# ATSAMA5D28CLD1G device description
Architecture: CORTEX-A5; Family: SAMA5; Series: SAMA5D2
Registers are 32-bit, read-write, no defined reset value unless marked. A register's access mark holds for its fields unless they carry their own. Offsets are from the block's base; [hi:lo] are bit positions; {n}, {i} and the like mark numbered series; <NAME> marks a mode.

## TWIHS — Two-wire Interface High Speed
Instances: TWIHS0 0xF8028000, TWIHS1 0xFC028000
0x00 TWIHS_CR wo (modes: DEFAULT when TWIHS_CR.FIFOEN=0; FIFO_ENABLED when TWIHS_CR.FIFOEN=1) — Control Register
  [29] FIFODIS <DEFAULT> — FIFO Disable
  [28] FIFOEN <DEFAULT> — FIFO Enable
  [26] LOCKCLR <DEFAULT> — Lock Clear
  [24] THRCLR <DEFAULT> — Transmit Holding Register Clear
  [17] ACMDIS <DEFAULT> — Alternative Command Mode Disable
  [16] ACMEN <DEFAULT> — Alternative Command Mode Enable
  [15] CLEAR <DEFAULT> — Bus CLEAR Command
  [14] PECRQ <DEFAULT> — PEC Request
  [13] PECDIS <DEFAULT> — Packet Error Checking Disable
  [12] PECEN <DEFAULT> — Packet Error Checking Enable
  [11] SMBDIS <DEFAULT> — SMBus Mode Disabled
  [10] SMBEN <DEFAULT> — SMBus Mode Enabled
  [9] HSDIS <DEFAULT> — TWIHS High-Speed Mode Disabled
  [8] HSEN <DEFAULT> — TWIHS High-Speed Mode Enabled
  [7] SWRST <DEFAULT> — Software Reset
  [6] QUICK <DEFAULT> — SMBus Quick Command
  [5] SVDIS <DEFAULT> — TWIHS Slave Mode Disabled
  [4] SVEN <DEFAULT> — TWIHS Slave Mode Enabled
  [3] MSDIS <DEFAULT> — TWIHS Master Mode Disabled
  [2] MSEN <DEFAULT> — TWIHS Master Mode Enabled
  [1] STOP <DEFAULT> — Send a STOP Condition
  [0] START <DEFAULT> — Send a START Condition
  [29] FIFODIS <FIFO_ENABLED> — FIFO Disable
  [28] FIFOEN <FIFO_ENABLED> — FIFO Enable
  [26] TXFLCLR <FIFO_ENABLED> — Transmit FIFO Lock CLEAR
  [25] RXFCLR <FIFO_ENABLED> — Receive FIFO Clear
  [24] TXFCLR <FIFO_ENABLED> — Transmit FIFO Clear
  [17] ACMDIS <FIFO_ENABLED> — Alternative Command Mode Disable
  [16] ACMEN <FIFO_ENABLED> — Alternative Command Mode Enable
  [15] CLEAR <FIFO_ENABLED> — Bus CLEAR Command
  [14] PECRQ <FIFO_ENABLED> — PEC Request
  [13] PECDIS <FIFO_ENABLED> — Packet Error Checking Disable
  [12] PECEN <FIFO_ENABLED> — Packet Error Checking Enable
  [11] SMBDIS <FIFO_ENABLED> — SMBus Mode Disabled
  [10] SMBEN <FIFO_ENABLED> — SMBus Mode Enabled
  [9] HSDIS <FIFO_ENABLED> — TWIHS High-Speed Mode Disabled
  [8] HSEN <FIFO_ENABLED> — TWIHS High-Speed Mode Enabled
  [7] SWRST <FIFO_ENABLED> — Software Reset
  [6] QUICK <FIFO_ENABLED> — SMBus Quick Command
  [5] SVDIS <FIFO_ENABLED> — TWIHS Slave Mode Disabled
  [4] SVEN <FIFO_ENABLED> — TWIHS Slave Mode Enabled
  [3] MSDIS <FIFO_ENABLED> — TWIHS Master Mode Disabled
  [2] MSEN <FIFO_ENABLED> — TWIHS Master Mode Enabled
  [1] STOP <FIFO_ENABLED> — Send a STOP Condition
  [0] START <FIFO_ENABLED> — Send a START Condition
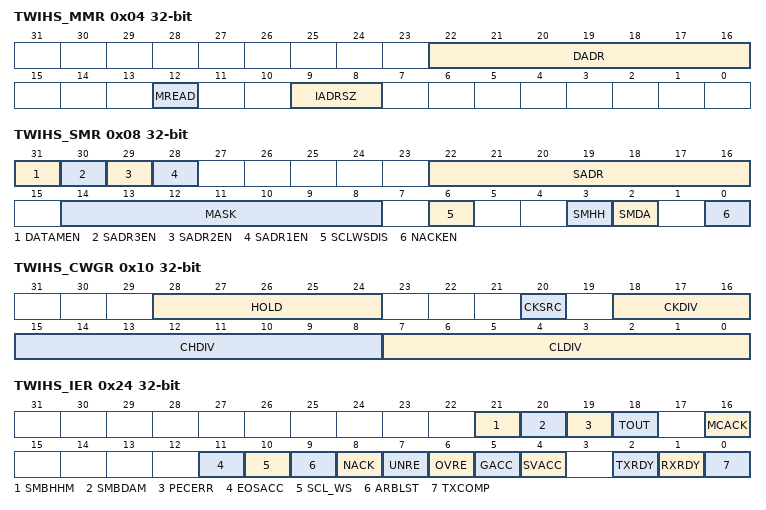
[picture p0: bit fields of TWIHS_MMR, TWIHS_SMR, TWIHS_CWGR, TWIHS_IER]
0x04 TWIHS_MMR — Master Mode Register
  [22:16] DADR — Device Address
  [12] MREAD — Master Read Direction
  [9:8] IADRSZ — Internal Device Address Size
    0=NONE (No internal device address); 1=_1_BYTE (One-byte internal device address); 2=_2_BYTE (Two-byte internal device address); 3=_3_BYTE (Three-byte internal device address)
0x08 TWIHS_SMR — Slave Mode Register
  [31] DATAMEN — Data Matching Enable
  [30] SADR3EN — Slave Address 3 Enable
  [29] SADR2EN — Slave Address 2 Enable
  [28] SADR1EN — Slave Address 1 Enable
  [22:16] SADR — Slave Address
  [14:8] MASK — Slave Address Mask
  [6] SCLWSDIS — Clock Wait State Disable
  [3] SMHH — SMBus Host Header
  [2] SMDA — SMBus Default Address
  [0] NACKEN — Slave Receiver Data Phase NACK enable
0x0C TWIHS_IADR — Internal Address Register
  [23:0] IADR — Internal Address
0x10 TWIHS_CWGR — Clock Waveform Generator Register
  [28:24] HOLD — TWD Hold Time Versus TWCK Falling
  [20] CKSRC — Transfer Rate Clock Source
    0=PERIPH_CK (Peripheral clock is used to generate the TWIHS baud rate.); 1=GCLK (GCLK is used to generate the TWIHS baud rate.)
  [18:16] CKDIV — Clock Divider
  [15:8] CHDIV — Clock High Divider
  [7:0] CLDIV — Clock Low Divider
0x20 TWIHS_SR ro (modes: DEFAULT when TWIHS_CR.FIFOEN=0; FIFO_ENABLED when TWIHS_CR.FIFOEN=1) — Status Register
  [25] SDA <DEFAULT> — SDA Line Value
  [24] SCL <DEFAULT> — SCL Line Value
  [23] LOCK <DEFAULT> — TWIHS Lock due to Frame Errors (cleared by writing a one to bit LOCKCLR in TWIHS_CR)
  [21] SMBHHM <DEFAULT> — SMBus Host Header Address Match (cleared on read)
  [20] SMBDAM <DEFAULT> — SMBus Default Address Match (cleared on read)
  [19] PECERR <DEFAULT> — PEC Error (cleared on read)
  [18] TOUT <DEFAULT> — Timeout Error (cleared on read)
  [16] MCACK <DEFAULT> — Master Code Acknowledge (cleared on read)
  [11] EOSACC <DEFAULT> — End Of Slave Access (cleared on read)
  [10] SCLWS <DEFAULT> — Clock Wait State
  [9] ARBLST <DEFAULT> — Arbitration Lost (cleared on read)
  [8] NACK <DEFAULT> — Not Acknowledged (cleared on read)
  [7] UNRE <DEFAULT> — Underrun Error (cleared on read)
  [6] OVRE <DEFAULT> — Overrun Error (cleared on read)
  [5] GACC <DEFAULT> — General Call Access (cleared on read)
  [4] SVACC <DEFAULT> — Slave Access
  [3] SVREAD <DEFAULT> — Slave Read
  [2] TXRDY <DEFAULT> — Transmit Holding Register Ready (cleared by writing TWIHS_THR)
  [1] RXRDY <DEFAULT> — Receive Holding Register Ready (cleared by reading TWIHS_RHR)
  [0] TXCOMP <DEFAULT> — Transmission Completed (cleared by writing TWIHS_THR)
  [25] SDA <FIFO_ENABLED> — SDA Line Value
  [24] SCL <FIFO_ENABLED> — SCL Line Value
  [23] TXFLOCK <FIFO_ENABLED> — Transmit FIFO Lock
  [21] SMBHHM <FIFO_ENABLED> — SMBus Host Header Address Match (cleared on read)
  [20] SMBDAM <FIFO_ENABLED> — SMBus Default Address Match (cleared on read)
  [19] PECERR <FIFO_ENABLED> — PEC Error (cleared on read)
  [18] TOUT <FIFO_ENABLED> — Timeout Error (cleared on read)
  [16] MCACK <FIFO_ENABLED> — Master Code Acknowledge (cleared on read)
  [11] EOSACC <FIFO_ENABLED> — End Of Slave Access (cleared on read)
  [10] SCLWS <FIFO_ENABLED> — Clock Wait State
  [9] ARBLST <FIFO_ENABLED> — Arbitration Lost (cleared on read)
  [8] NACK <FIFO_ENABLED> — Not Acknowledged (cleared on read)
  [7] UNRE <FIFO_ENABLED> — Underrun Error (cleared on read)
  [6] OVRE <FIFO_ENABLED> — Overrun Error (cleared on read)
  [5] GACC <FIFO_ENABLED> — General Call Access (cleared on read)
  [4] SVACC <FIFO_ENABLED> — Slave Access
  [3] SVREAD <FIFO_ENABLED> — Slave Read
  [2] TXRDY <FIFO_ENABLED> — Transmit Holding Register Ready (cleared by writing TWIHS_THR)
  [1] RXRDY <FIFO_ENABLED> — Receive Holding Register Ready (cleared by reading TWIHS_RHR)
  [0] TXCOMP <FIFO_ENABLED> — Transmission Completed (cleared by writing TWIHS_THR)
0x24 TWIHS_IER wo (atomic set of TWIHS_IMR) — Interrupt Enable Register
  [21] SMBHHM — SMBus Host Header Address Match Interrupt Enable
  [20] SMBDAM — SMBus Default Address Match Interrupt Enable
  [19] PECERR — PEC Error Interrupt Enable
  [18] TOUT — Timeout Error Interrupt Enable
  [16] MCACK — Master Code Acknowledge Interrupt Enable
  [11] EOSACC — End Of Slave Access Interrupt Enable
  [10] SCL_WS — Clock Wait State Interrupt Enable
  [9] ARBLST — Arbitration Lost Interrupt Enable
  [8] NACK — Not Acknowledge Interrupt Enable
  [7] UNRE — Underrun Error Interrupt Enable
  [6] OVRE — Overrun Error Interrupt Enable
  [5] GACC — General Call Access Interrupt Enable
  [4] SVACC — Slave Access Interrupt Enable
  [2] TXRDY — Transmit Holding Register Ready Interrupt Enable
  [1] RXRDY — Receive Holding Register Ready Interrupt Enable
  [0] TXCOMP — Transmission Completed Interrupt Enable
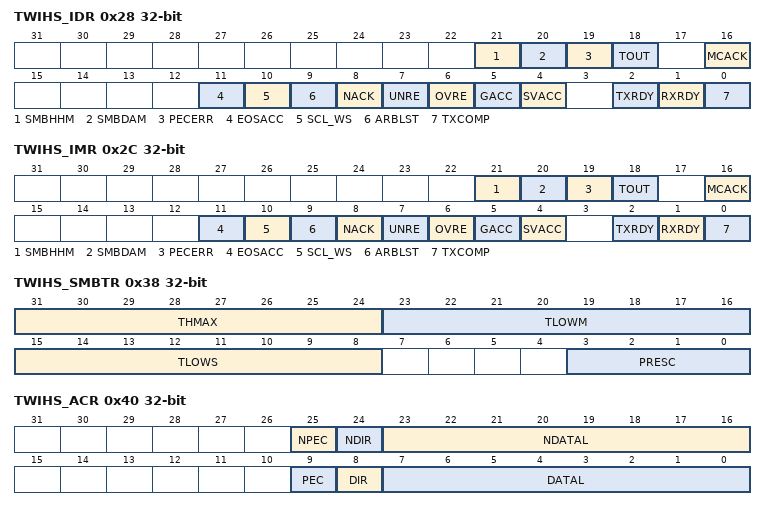
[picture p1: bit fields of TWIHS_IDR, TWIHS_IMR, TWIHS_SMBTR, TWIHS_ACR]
0x28 TWIHS_IDR wo (atomic clear of TWIHS_IMR) — Interrupt Disable Register
  [21] SMBHHM — SMBus Host Header Address Match Interrupt Disable
  [20] SMBDAM — SMBus Default Address Match Interrupt Disable
  [19] PECERR — PEC Error Interrupt Disable
  [18] TOUT — Timeout Error Interrupt Disable
  [16] MCACK — Master Code Acknowledge Interrupt Disable
  [11] EOSACC — End Of Slave Access Interrupt Disable
  [10] SCL_WS — Clock Wait State Interrupt Disable
  [9] ARBLST — Arbitration Lost Interrupt Disable
  [8] NACK — Not Acknowledge Interrupt Disable
  [7] UNRE — Underrun Error Interrupt Disable
  [6] OVRE — Overrun Error Interrupt Disable
  [5] GACC — General Call Access Interrupt Disable
  [4] SVACC — Slave Access Interrupt Disable
  [2] TXRDY — Transmit Holding Register Ready Interrupt Disable
  [1] RXRDY — Receive Holding Register Ready Interrupt Disable
  [0] TXCOMP — Transmission Completed Interrupt Disable
0x2C TWIHS_IMR ro (atomic read) — Interrupt Mask Register
  [21] SMBHHM — SMBus Host Header Address Match Interrupt Mask
  [20] SMBDAM — SMBus Default Address Match Interrupt Mask
  [19] PECERR — PEC Error Interrupt Mask
  [18] TOUT — Timeout Error Interrupt Mask
  [16] MCACK — Master Code Acknowledge Interrupt Mask
  [11] EOSACC — End Of Slave Access Interrupt Mask
  [10] SCL_WS — Clock Wait State Interrupt Mask
  [9] ARBLST — Arbitration Lost Interrupt Mask
  [8] NACK — Not Acknowledge Interrupt Mask
  [7] UNRE — Underrun Error Interrupt Mask
  [6] OVRE — Overrun Error Interrupt Mask
  [5] GACC — General Call Access Interrupt Mask
  [4] SVACC — Slave Access Interrupt Mask
  [2] TXRDY — Transmit Holding Register Ready Interrupt Mask
  [1] RXRDY — Receive Holding Register Ready Interrupt Mask
  [0] TXCOMP — Transmission Completed Interrupt Mask
0x30 TWIHS_RHR ro (modes: DEFAULT when TWIHS_CR.FIFOEN=0; FIFO_ENABLED when TWIHS_CR.FIFOEN=1) — Receive Holding Register
  [7:0] RXDATA <DEFAULT> — Master or Slave Receive Holding Data
  [8n+7:8n] RXDATA{n} <FIFO_ENABLED> (n=0..3) — Master or Slave Receive Holding Data {n}
0x34 TWIHS_THR wo (modes: DEFAULT when TWIHS_CR.FIFOEN=0; FIFO_ENABLED when TWIHS_CR.FIFOEN=1) — Transmit Holding Register
  [7:0] TXDATA <DEFAULT> — Master or Slave Transmit Holding Data
  [31:24] TXDATA3 <FIFO_ENABLED> — Master or Slave Transmit Holding Data 3
  [23:16] TXDATA2 <FIFO_ENABLED> — Master or Slave Transmit Holding Data 2
  [15:8] TXDATA1 <FIFO_ENABLED> — Master or Slave Transmit Holding Data 1
  [7:0] TXDATA0 <FIFO_ENABLED> — Master or Slave Transmit Holding Data 02
0x38 TWIHS_SMBTR — SMBus Timing Register
  [31:24] THMAX — Clock High Maximum Cycles
  [23:16] TLOWM — Master Clock Stretch Maximum Cycles
  [15:8] TLOWS — Slave Clock Stretch Maximum Cycles
  [3:0] PRESC — SMBus Clock Prescaler
0x40 TWIHS_ACR — Alternative Command Register
  [25] NPEC — Next PEC Request (SMBus Mode only)
  [24] NDIR — Next Transfer Direction
  [23:16] NDATAL — Next Data Length
  [9] PEC — PEC Request (SMBus Mode only)
  [8] DIR — Transfer Direction
  [7:0] DATAL — Data Length
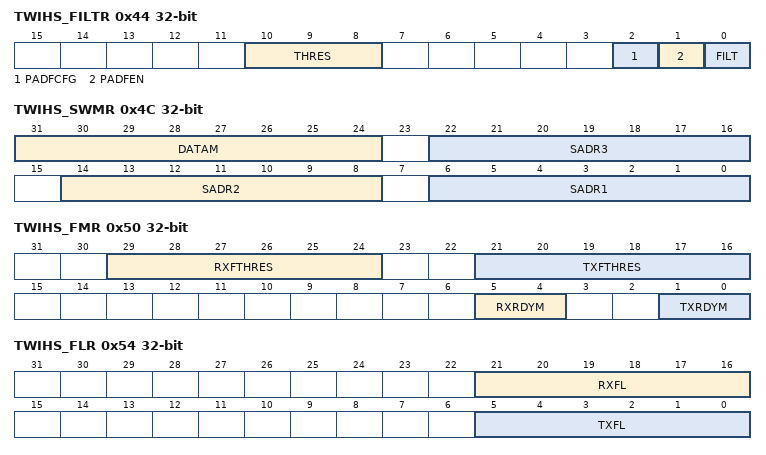
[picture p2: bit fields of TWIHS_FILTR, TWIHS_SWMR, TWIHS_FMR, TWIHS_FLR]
0x44 TWIHS_FILTR — Filter Register
  [10:8] THRES — Digital Filter Threshold
  [2] PADFCFG — PAD Filter Config
  [1] PADFEN — PAD Filter Enable
  [0] FILT — RX Digital Filter
0x4C TWIHS_SWMR — SleepWalking Matching Register
  [31:24] DATAM — Data Match
  [22:16] SADR3 — Slave Address 3
  [14:8] SADR2 — Slave Address 2
  [6:0] SADR1 — Slave Address 1
0x50 TWIHS_FMR — FIFO Mode Register
  [29:24] RXFTHRES — Receive FIFO Threshold
  [21:16] TXFTHRES — Transmit FIFO Threshold
  [5:4] RXRDYM — Receiver Ready Mode
    0=ONE_DATA (RXRDY will be at level '1' when at least one unread data is in the Receive FIFO); 1=TWO_DATA (RXRDY will be at level '1' when at least two unread data are in the Receive FIFO); 2=FOUR_DATA (RXRDY will be at level '1' when at least four unread data are in the Receive FIFO)
  [1:0] TXRDYM — Transmitter Ready Mode
    0=ONE_DATA (TXRDY will be at level '1' when at least one data can be written in the Transmit FIFO); 1=TWO_DATA (TXRDY will be at level '1' when at least two data can be written in the Transmit FIFO); 2=FOUR_DATA (TXRDY will be at level '1' when at least four data can be written in the Transmit FIFO)
0x54 TWIHS_FLR ro — FIFO Level Register
  [21:16] RXFL — Receive FIFO Level
  [5:0] TXFL — Transmit FIFO Level
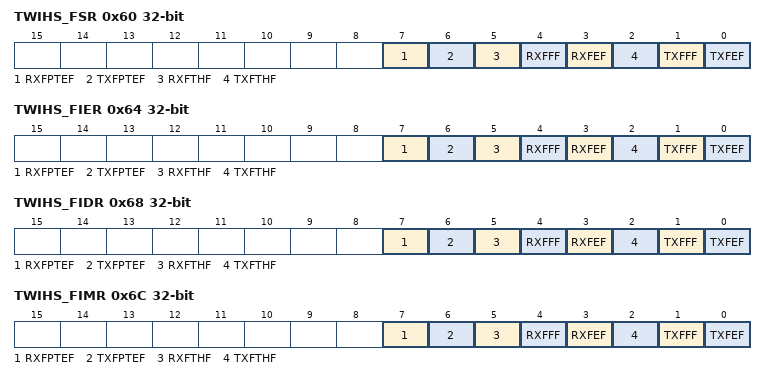
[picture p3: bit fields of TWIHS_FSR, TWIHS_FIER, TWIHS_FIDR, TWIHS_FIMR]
0x60 TWIHS_FSR ro — FIFO Status Register
  [7] RXFPTEF — Receive FIFO Pointer Error Flag
  [6] TXFPTEF — Transmit FIFO Pointer Error Flag
  [5] RXFTHF — Receive FIFO Threshold Flag
  [4] RXFFF — Receive FIFO Full Flag
  [3] RXFEF — Receive FIFO Empty Flag
  [2] TXFTHF — Transmit FIFO Threshold Flag (cleared on read)
  [1] TXFFF — Transmit FIFO Full Flag (cleared on read)
  [0] TXFEF — Transmit FIFO Empty Flag (cleared on read)
0x64 TWIHS_FIER wo — FIFO Interrupt Enable Register
  [7] RXFPTEF — RXFPTEF Interrupt Enable
  [6] TXFPTEF — TXFPTEF Interrupt Enable
  [5] RXFTHF — RXFTHF Interrupt Enable
  [4] RXFFF — RXFFF Interrupt Enable
  [3] RXFEF — RXFEF Interrupt Enable
  [2] TXFTHF — TXFTHF Interrupt Enable
  [1] TXFFF — TXFFF Interrupt Enable
  [0] TXFEF — TXFEF Interrupt Enable
0x68 TWIHS_FIDR wo — FIFO Interrupt Disable Register
  [7] RXFPTEF — RXFPTEF Interrupt Disable
  [6] TXFPTEF — TXFPTEF Interrupt Disable
  [5] RXFTHF — RXFTHF Interrupt Disable
  [4] RXFFF — RXFFF Interrupt Disable
  [3] RXFEF — RXFEF Interrupt Disable
  [2] TXFTHF — TXFTHF Interrupt Disable
  [1] TXFFF — TXFFF Interrupt Disable
  [0] TXFEF — TXFEF Interrupt Disable
0x6C TWIHS_FIMR ro — FIFO Interrupt Mask Register
  [7] RXFPTEF — RXFPTEF Interrupt Mask
  [6] TXFPTEF — TXFPTEF Interrupt Mask
  [5] RXFTHF — RXFTHF Interrupt Mask
  [4] RXFFF — RXFFF Interrupt Mask
  [3] RXFEF — RXFEF Interrupt Mask
  [2] TXFTHF — TXFTHF Interrupt Mask
  [1] TXFFF — TXFFF Interrupt Mask
  [0] TXFEF — TXFEF Interrupt Mask
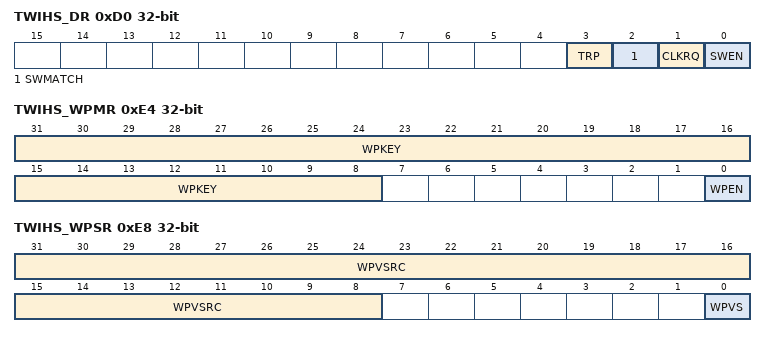
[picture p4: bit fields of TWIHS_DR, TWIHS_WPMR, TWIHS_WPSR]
0xD0 TWIHS_DR ro — Debug Register
  [3] TRP — Transfer Pending
  [2] SWMATCH — SleepWalking Match
  [1] CLKRQ — Clock Request
  [0] SWEN — SleepWalking Enable
0xE4 TWIHS_WPMR — Write Protection Mode Register
  [31:8] WPKEY — Write Protection Key
    0x545749=PASSWD (Writing any other value in this field aborts the write operation of the WPEN bit.Always reads as 0)
  [0] WPEN — Write Protection Enable
0xE8 TWIHS_WPSR ro — Write Protection Status Register
  [31:8] WPVSRC — Write Protection Violation Source
  [0] WPVS — Write Protection Violation Status
